# ESP32-S3 register map
Vendor: ESPRESSIF SYSTEMS (SHANGHAI) CO., LTD.; Series: ESP32 S-Series; File version: 22
CPU: Xtensa LX7 r0p0, little endian, no MPU, FPU, 0 interrupt priority bits
Address unit: 32 bits
Registers are 32-bit, read-write, reset 0x0 unless marked. A register's access mark holds for its fields unless they carry their own. Offsets are from the block's base; [hi:lo] are bit positions; {n}, {i} and the like mark numbered series.

## MCPWM0 — Motor Control Pulse-Width Modulation 0
Base 0x6001E000
Same registers: MCPWM1 0x6002C000
0x00 CLK_CFG — PWM clock prescaler register.
  [7:0] CLK_PRESCALE — Period of PWM_clk = 6.25ns * (PWM_CLK_PRESCALE + 1)
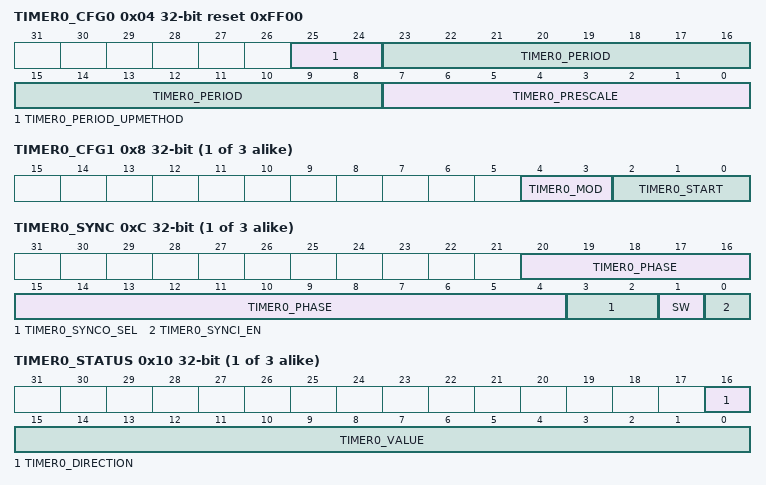
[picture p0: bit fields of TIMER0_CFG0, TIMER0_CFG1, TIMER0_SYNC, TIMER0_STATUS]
0x04 TIMER0_CFG0 reset 0xFF00 — PWM timer0 period and update method configuration register.
  [25:24] TIMER0_PERIOD_UPMETHOD — Update method for active register of PWM timer0 period, 0: immediate, 1: TEZ, 2: sync, 3: TEZ | sync. TEZ here and below means timer equal zero event
  [23:8] TIMER0_PERIOD — period shadow register of PWM timer0
  [7:0] TIMER0_PRESCALE — period of PT0_clk = Period of PWM_clk * (PWM_TIMER0_PRESCALE + 1)
{0x8+0x10*i} TIMER{i}_CFG1 (i=0..2) — PWM timer{i} working mode and start/stop control configuration register.
  [4:3] TIMER{i}_MOD — PWM timer{i} working mode, 0: freeze, 1: increase mode, 2: decrease mode, 3: up-down mode
  [2:0] TIMER{i}_START — PWM timer{i} start and stop control. 0: if PWM timer{i} starts, then stops at TEZ, 1: if timer{i} starts, then stops at TEP, 2: PWM timer{i} starts and runs on, 3: timer{i} starts and stops at the next TEZ, 4: timer{i} starts and stops at the next TEP. TEP here and below means the event that happens when the timer equals to period
{0xC+0x10*i} TIMER{i}_SYNC (i=0..2) — PWM timer{i} sync function configuration register.
  [20:4] TIMER{i}_PHASE — phase for timer reload on sync event
  [3:2] TIMER{i}_SYNCO_SEL — PWM timer{i} sync_out selection, 0: synci, 1: TEZ, 2: TEP, otherwise:sync out is software sync
  [1] SW — Toggling this bit will trigger a software sync.
  [0] TIMER{i}_SYNCI_EN — When set, timer reloading with phase on sync input event is enabled.
{0x10+0x10*i} TIMER{i}_STATUS ro (i=0..2) — PWM timer{i} status register.
  [16] TIMER{i}_DIRECTION — current PWM timer{i} counter direction, 0: increment 1: decrement
  [15:0] TIMER{i}_VALUE — current PWM timer{i} counter value
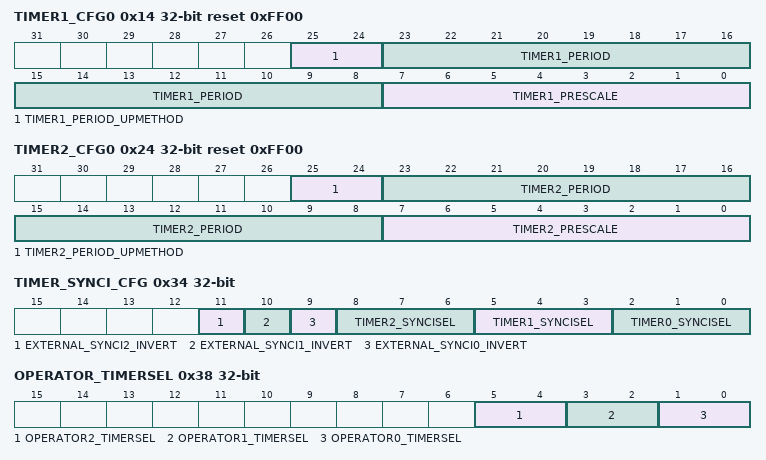
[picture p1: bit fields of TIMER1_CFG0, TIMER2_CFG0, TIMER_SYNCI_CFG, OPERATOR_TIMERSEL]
0x14 TIMER1_CFG0 reset 0xFF00 — PWM timer1 period and update method configuration register.
  [25:24] TIMER1_PERIOD_UPMETHOD — Update method for active register of PWM timer1 period, 0: immediate, 1: TEZ, 2: sync, 3: TEZ | sync. TEZ here and below means timer equal zero event
  [23:8] TIMER1_PERIOD — period shadow register of PWM timer1
  [7:0] TIMER1_PRESCALE — period of PT0_clk = Period of PWM_clk * (PWM_timer1_PRESCALE + 1)
0x24 TIMER2_CFG0 reset 0xFF00 — PWM timer2 period and update method configuration register.
  [25:24] TIMER2_PERIOD_UPMETHOD — Update method for active register of PWM timer2 period, 0: immediate, 1: TEZ, 2: sync, 3: TEZ | sync. TEZ here and below means timer equal zero event
  [23:8] TIMER2_PERIOD — period shadow register of PWM timer2
  [7:0] TIMER2_PRESCALE — period of PT0_clk = Period of PWM_clk * (PWM_timer2_PRESCALE + 1)
0x34 TIMER_SYNCI_CFG — Synchronization input selection for three PWM timers.
  [11] EXTERNAL_SYNCI2_INVERT — invert SYNC2 from GPIO matrix
  [10] EXTERNAL_SYNCI1_INVERT — invert SYNC1 from GPIO matrix
  [9] EXTERNAL_SYNCI0_INVERT — invert SYNC0 from GPIO matrix
  [8:6] TIMER2_SYNCISEL — select sync input for PWM timer2, 1: PWM timer0 sync_out, 2: PWM timer1 sync_out, 3: PWM timer2 sync_out, 4: SYNC0 from GPIO matrix, 5: SYNC1 from GPIO matrix, 6: SYNC2 from GPIO matrix, other values: no sync input selected
  [5:3] TIMER1_SYNCISEL — select sync input for PWM timer1, 1: PWM timer0 sync_out, 2: PWM timer1 sync_out, 3: PWM timer2 sync_out, 4: SYNC0 from GPIO matrix, 5: SYNC1 from GPIO matrix, 6: SYNC2 from GPIO matrix, other values: no sync input selected
  [2:0] TIMER0_SYNCISEL — select sync input for PWM timer0, 1: PWM timer0 sync_out, 2: PWM timer1 sync_out, 3: PWM timer2 sync_out, 4: SYNC0 from GPIO matrix, 5: SYNC1 from GPIO matrix, 6: SYNC2 from GPIO matrix, other values: no sync input selected
0x38 OPERATOR_TIMERSEL — Select specific timer for PWM operators.
  [5:4] OPERATOR2_TIMERSEL — Select which PWM timer's is the timing reference for PWM operator2, 0: timer0, 1: timer1, 2: timer2
  [3:2] OPERATOR1_TIMERSEL — Select which PWM timer's is the timing reference for PWM operator1, 0: timer0, 1: timer1, 2: timer2
  [1:0] OPERATOR0_TIMERSEL — Select which PWM timer's is the timing reference for PWM operator0, 0: timer0, 1: timer1, 2: timer2
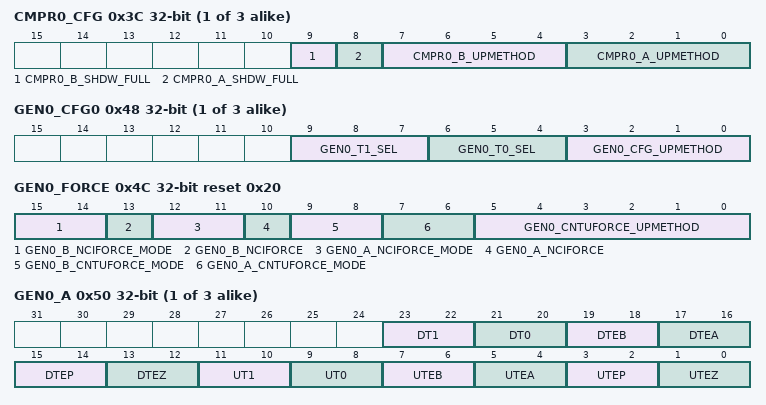
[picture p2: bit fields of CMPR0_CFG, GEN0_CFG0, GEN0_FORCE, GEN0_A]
{0x3C+0x38*i} CMPR{i}_CFG (i=0..2) — Transfer status and update method for time stamp registers A and B
  [9] CMPR{i}_B_SHDW_FULL — Set and reset by hardware. If set, PWM generator {i} time stamp B's shadow reg is filled and waiting to be transferred to B's active reg. If cleared, B's active reg has been updated with shadow register latest value
  [8] CMPR{i}_A_SHDW_FULL — Set and reset by hardware. If set, PWM generator {i} time stamp A's shadow reg is filled and waiting to be transferred to A's active reg. If cleared, A's active reg has been updated with shadow register latest value
  [7:4] CMPR{i}_B_UPMETHOD — Update method for PWM generator {i} time stamp B's active register. When all bits are set to 0: immediately, when bit0 is set to 1: TEZ, when bit1 is set to 1: TEP,when bit2 is set to 1: sync, when bit3 is set to 1: disable the update.
  [3:0] CMPR{i}_A_UPMETHOD — Update method for PWM generator {i} time stamp A's active register. When all bits are set to 0: immediately, when bit0 is set to 1: TEZ, when bit1 is set to 1: TEP,when bit2 is set to 1: sync, when bit3 is set to 1: disable the update.
{0x40+0x38*i} CMPR{i}_VALUE0 (i=0..2) — Shadow register for register A.
  [15:0] CMPR{i}_A — PWM generator {i} time stamp A's shadow register
{0x44+0x38*i} CMPR{i}_VALUE1 (i=0..2) — Shadow register for register B.
  [15:0] CMPR{i}_B — PWM generator {i} time stamp B's shadow register
{0x48+0x38*i} GEN{i}_CFG0 (i=0..2) — Fault event T0 and T1 handling
  [9:7] GEN{i}_T1_SEL — Source selection for PWM generator {i} event_t1, take effect immediately, 0: fault_event0, 1: fault_event1, 2: fault_event2, 3: sync_taken, 4: none
  [6:4] GEN{i}_T0_SEL — Source selection for PWM generator {i} event_t0, take effect immediately, 0: fault_event0, 1: fault_event1, 2: fault_event2, 3: sync_taken, 4: none
  [3:0] GEN{i}_CFG_UPMETHOD — Update method for PWM generator {i}'s active register of configuration. When all bits are set to 0: immediately, when bit0 is set to 1: TEZ, when bit1 is set to 1:
0x4C GEN0_FORCE reset 0x20 — Permissives to force PWM0A and PWM0B outputs by software
  [15:14] GEN0_B_NCIFORCE_MODE — non-continuous immediate software force mode for PWM0B, 0: disabled, 1: low, 2: high, 3: disabled
  [13] GEN0_B_NCIFORCE — Trigger of non-continuous immediate software-force event for PWM0B, a toggle will trigger a force event.
  [12:11] GEN0_A_NCIFORCE_MODE — non-continuous immediate software force mode for PWM0A, 0: disabled, 1: low, 2: high, 3: disabled
  [10] GEN0_A_NCIFORCE — Trigger of non-continuous immediate software-force event for PWM0A, a toggle will trigger a force event.
  [9:8] GEN0_B_CNTUFORCE_MODE — Continuous software force mode for PWM0B. 0: disabled, 1: low, 2: high, 3: disabled
  [7:6] GEN0_A_CNTUFORCE_MODE — Continuous software force mode for PWM0A. 0: disabled, 1: low, 2: high, 3: disabled
  [5:0] GEN0_CNTUFORCE_UPMETHOD — Updating method for continuous software force of PWM generator0. When all bits are set to 0: immediately, when bit0 is set to 1: TEZ,,when bit1 is set to 1: TEP, when bit2 is set to 1: TEA, when bit3 is set to 1: TEB, when bit4 is set to 1: sync, when bit5 is set to 1: disable update. (TEA/B here and below means an event generated when the timer's value equals to that of register A/B.)
{0x50+0x38*i} GEN{i}_A (i=0..2) — Actions triggered by events on PWM{i}A
  [23:22] DT1 — Action on PWM{i}A triggered by event_t1 when timer decreasing. 0: no change, 1: low, 2: high, 3: toggle
  [21:20] DT0 — Action on PWM{i}A triggered by event_t0 when timer decreasing
  [19:18] DTEB — Action on PWM{i}A triggered by event TEB when timer decreasing
  [17:16] DTEA — Action on PWM{i}A triggered by event TEA when timer decreasing
  [15:14] DTEP — Action on PWM{i}A triggered by event TEP when timer decreasing
  [13:12] DTEZ — Action on PWM{i}A triggered by event TEZ when timer decreasing
  [11:10] UT1 — Action on PWM{i}A triggered by event_t1 when timer increasing
  [9:8] UT0 — Action on PWM{i}A triggered by event_t0 when timer increasing
  [7:6] UTEB — Action on PWM{i}A triggered by event TEB when timer increasing
  [5:4] UTEA — Action on PWM{i}A triggered by event TEA when timer increasing
  [3:2] UTEP — Action on PWM{i}A triggered by event TEP when timer increasing
  [1:0] UTEZ — Action on PWM{i}A triggered by event TEZ when timer increasing
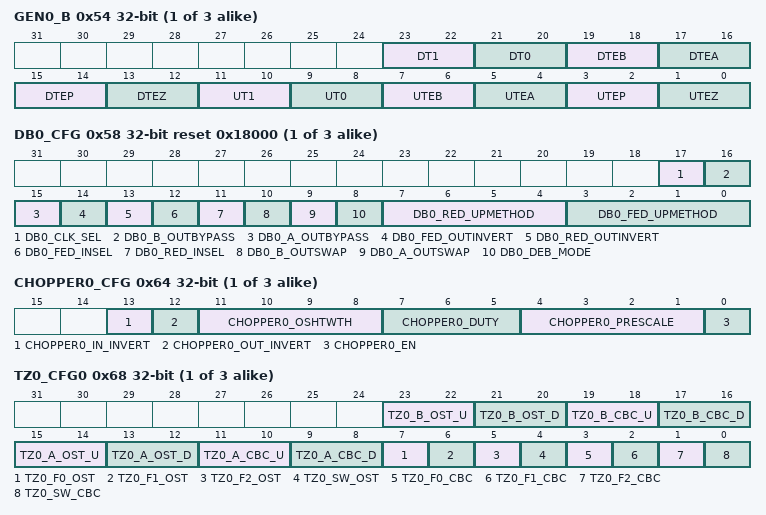
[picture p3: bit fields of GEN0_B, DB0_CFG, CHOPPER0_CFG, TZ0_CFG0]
{0x54+0x38*i} GEN{i}_B (i=0..2) — Actions triggered by events on PWM{i}B
  [23:22] DT1 — Action on PWM{i}B triggered by event_t1 when timer decreasing. 0: no change, 1: low, 2: high, 3: toggle
  [21:20] DT0 — Action on PWM{i}B triggered by event_t0 when timer decreasing
  [19:18] DTEB — Action on PWM{i}B triggered by event TEB when timer decreasing
  [17:16] DTEA — Action on PWM{i}B triggered by event TEA when timer decreasing
  [15:14] DTEP — Action on PWM{i}B triggered by event TEP when timer decreasing
  [13:12] DTEZ — Action on PWM{i}B triggered by event TEZ when timer decreasing
  [11:10] UT1 — Action on PWM{i}B triggered by event_t1 when timer increasing
  [9:8] UT0 — Action on PWM{i}B triggered by event_t0 when timer increasing
  [7:6] UTEB — Action on PWM{i}B triggered by event TEB when timer increasing
  [5:4] UTEA — Action on PWM{i}B triggered by event TEA when timer increasing
  [3:2] UTEP — Action on PWM{i}B triggered by event TEP when timer increasing
  [1:0] UTEZ — Action on PWM{i}B triggered by event TEZ when timer increasing
{0x58+0x38*i} DB{i}_CFG reset 0x18000 (i=0..2) — dead time type selection and configuration
  [17] DB{i}_CLK_SEL — Dead time generator {i} clock selection. 0: PWM_clk, 1: PT_clk
  [16] DB{i}_B_OUTBYPASS — S0 in documentation
  [15] DB{i}_A_OUTBYPASS — S1 in documentation
  [14] DB{i}_FED_OUTINVERT — S3 in documentation
  [13] DB{i}_RED_OUTINVERT — S2 in documentation
  [12] DB{i}_FED_INSEL — S5 in documentation
  [11] DB{i}_RED_INSEL — S4 in documentation
  [10] DB{i}_B_OUTSWAP — S7 in documentation
  [9] DB{i}_A_OUTSWAP — S6 in documentation
  [8] DB{i}_DEB_MODE — S8 in documentation, dual-edge B mode, 0: fed/red take effect on different path separately, 1: fed/red take effect on B path, A out is in bypass or dulpB mode
  [7:4] DB{i}_RED_UPMETHOD — Update method for RED (rising edge delay) active register. 0: immediate, bit0: tez, bit1: tep, bit2: sync, bit3: freeze
  [3:0] DB{i}_FED_UPMETHOD — Update method for FED (falling edge delay) active register. 0: immediate, bit0: tez, bit1: tep, bit2: sync, bit3: freeze
{0x5C+0x38*i} DB{i}_FED_CFG (i=0..2) — Shadow register for falling edge delay (FED).
  [15:0] DB{i}_FED — Shadow register for FED
{0x60+0x38*i} DB{i}_RED_CFG (i=0..2) — Shadow register for rising edge delay (RED).
  [15:0] DB{i}_RED — Shadow register for RED
{0x64+0x38*i} CHOPPER{i}_CFG (i=0..2) — Carrier enable and configuratoin
  [13] CHOPPER{i}_IN_INVERT — when set, invert the input of PWM{i}A and PWM{i}B for this submodule
  [12] CHOPPER{i}_OUT_INVERT — when set, invert the output of PWM{i}A and PWM{i}B for this submodule
  [11:8] CHOPPER{i}_OSHTWTH — width of the fist pulse in number of periods of the carrier
  [7:5] CHOPPER{i}_DUTY — carrier duty selection. Duty = PWM_CARRIER0_DUTY / 8
  [4:1] CHOPPER{i}_PRESCALE — PWM carrier0 clock (PC_clk) prescale value. Period of PC_clk = period of PWM_clk * (PWM_CARRIER0_PRESCALE + 1)
  [0] CHOPPER{i}_EN — When set, carrier0 function is enabled. When cleared, carrier0 is bypassed
{0x68+0x38*i} TZ{i}_CFG0 (i=0..2) — Actions on PWM{i}A and PWM{i}B trip events
  [23:22] TZ{i}_B_OST_U — One-shot mode action on PWM{i}B when fault event occurs and timer is increasing. 0: do nothing, 1: force lo, 2: force hi, 3: toggle
  [21:20] TZ{i}_B_OST_D — One-shot mode action on PWM{i}B when fault event occurs and timer is decreasing. 0: do nothing, 1: force lo, 2: force hi, 3: toggle
  [19:18] TZ{i}_B_CBC_U — Cycle-by-cycle mode action on PWM{i}B when fault event occurs and timer is increasing. 0: do nothing, 1: force lo, 2: force hi, 3: toggle
  [17:16] TZ{i}_B_CBC_D — Cycle-by-cycle mode action on PWM{i}B when fault event occurs and timer is decreasing. 0: do nothing, 1: force lo, 2: force hi, 3: toggle
  [15:14] TZ{i}_A_OST_U — One-shot mode action on PWM{i}A when fault event occurs and timer is increasing. 0: do nothing, 1: force lo, 2: force hi, 3: toggle
  [13:12] TZ{i}_A_OST_D — One-shot mode action on PWM{i}A when fault event occurs and timer is decreasing. 0: do nothing, 1: force lo, 2: force hi, 3: toggle
  [11:10] TZ{i}_A_CBC_U — Cycle-by-cycle mode action on PWM{i}A when fault event occurs and timer is increasing. 0: do nothing, 1: force lo, 2: force hi, 3: toggle
  [9:8] TZ{i}_A_CBC_D — Cycle-by-cycle mode action on PWM{i}A when fault event occurs and timer is decreasing. 0: do nothing, 1: force lo, 2: force hi, 3: toggle
  [7] TZ{i}_F0_OST — event_f0 will trigger one-shot mode action. 0: disable, 1: enable
  [6] TZ{i}_F1_OST — event_f1 will trigger one-shot mode action. 0: disable, 1: enable
  [5] TZ{i}_F2_OST — event_f2 will trigger one-shot mode action. 0: disable, 1: enable
  [4] TZ{i}_SW_OST — Enable register for software force one-shot mode action. 0: disable, 1: enable
  [3] TZ{i}_F0_CBC — event_f0 will trigger cycle-by-cycle mode action. 0: disable, 1: enable
  [2] TZ{i}_F1_CBC — event_f1 will trigger cycle-by-cycle mode action. 0: disable, 1: enable
  [1] TZ{i}_F2_CBC — event_f2 will trigger cycle-by-cycle mode action. 0: disable, 1: enable
  [0] TZ{i}_SW_CBC — Enable register for software force cycle-by-cycle mode action. 0: disable, 1: enable
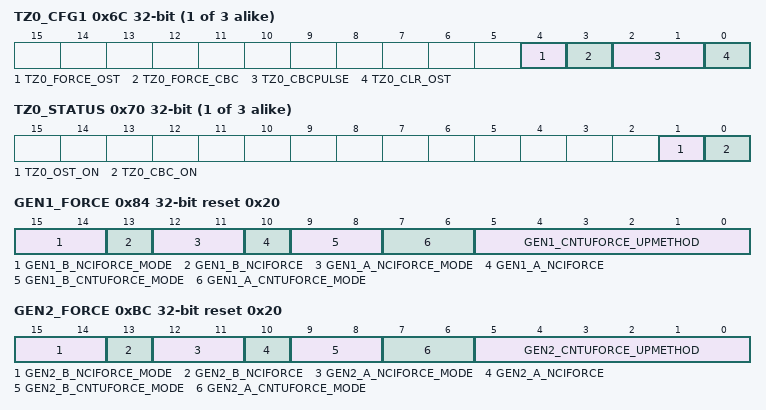
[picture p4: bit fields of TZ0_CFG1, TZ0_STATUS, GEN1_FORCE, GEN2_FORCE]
{0x6C+0x38*i} TZ{i}_CFG1 (i=0..2) — Software triggers for fault handler actions
  [4] TZ{i}_FORCE_OST — a toggle (software negate its value) triggers a one-shot mode action
  [3] TZ{i}_FORCE_CBC — a toggle trigger a cycle-by-cycle mode action
  [2:1] TZ{i}_CBCPULSE — cycle-by-cycle mode action refresh moment selection. Bit0: TEZ, bit1:TEP
  [0] TZ{i}_CLR_OST — a rising edge will clear on going one-shot mode action
{0x70+0x38*i} TZ{i}_STATUS ro (i=0..2) — Status of fault events.
  [1] TZ{i}_OST_ON — Set and reset by hardware. If set, an one-shot mode action is on going
  [0] TZ{i}_CBC_ON — Set and reset by hardware. If set, a cycle-by-cycle mode action is on going
0x84 GEN1_FORCE reset 0x20 — Permissives to force PWM1A and PWM1B outputs by software
  [15:14] GEN1_B_NCIFORCE_MODE — non-continuous immediate software force mode for PWM1B, 0: disabled, 1: low, 2: high, 3: disabled
  [13] GEN1_B_NCIFORCE — Trigger of non-continuous immediate software-force event for PWM1B, a toggle will trigger a force event.
  [12:11] GEN1_A_NCIFORCE_MODE — non-continuous immediate software force mode for PWM1A, 0: disabled, 1: low, 2: high, 3: disabled
  [10] GEN1_A_NCIFORCE — Trigger of non-continuous immediate software-force event for PWM1A, a toggle will trigger a force event.
  [9:8] GEN1_B_CNTUFORCE_MODE — Continuous software force mode for PWM1B. 0: disabled, 1: low, 2: high, 3: disabled
  [7:6] GEN1_A_CNTUFORCE_MODE — Continuous software force mode for PWM1A. 0: disabled, 1: low, 2: high, 3: disabled
  [5:0] GEN1_CNTUFORCE_UPMETHOD — Updating method for continuous software force of PWM generator 1. When all bits are set to 0: immediately, when bit0 is set to 1: TEZ,,when bit1 is set to 1: TEP, when bit2 is set to 1: TEA, when bit3 is set to 1: TEB, when bit4 is set to 1: sync, when bit5 is set to 1: disable update. (TEA/B here and below means an event generated when the timer's value equals to that of register A/B.)
0xBC GEN2_FORCE reset 0x20 — Permissives to force PWM2A and PWM2B outputs by software
  [15:14] GEN2_B_NCIFORCE_MODE — non-continuous immediate software force mode for PWM2B, 0: disabled, 1: low, 2: high, 3: disabled
  [13] GEN2_B_NCIFORCE — Trigger of non-continuous immediate software-force event for PWM2B, a toggle will trigger a force event.
  [12:11] GEN2_A_NCIFORCE_MODE — non-continuous immediate software force mode for PWM2A, 0: disabled, 1: low, 2: high, 3: disabled
  [10] GEN2_A_NCIFORCE — Trigger of non-continuous immediate software-force event for PWM2A, a toggle will trigger a force event.
  [9:8] GEN2_B_CNTUFORCE_MODE — Continuous software force mode for PWM2B. 0: disabled, 1: low, 2: high, 3: disabled
  [7:6] GEN2_A_CNTUFORCE_MODE — Continuous software force mode for PWM2A. 0: disabled, 1: low, 2: high, 3: disabled
  [5:0] GEN2_CNTUFORCE_UPMETHOD — Updating method for continuous software force of PWM generator 2. When all bits are set to 0: immediately, when bit0 is set to 1: TEZ,,when bit1 is set to 1: TEP, when bit2 is set to 1: TEA, when bit3 is set to 1: TEB, when bit4 is set to 1: sync, when bit5 is set to 1: disable update. (TEA/B here and below means an event generated when the timer's value equals to that of register A/B.)
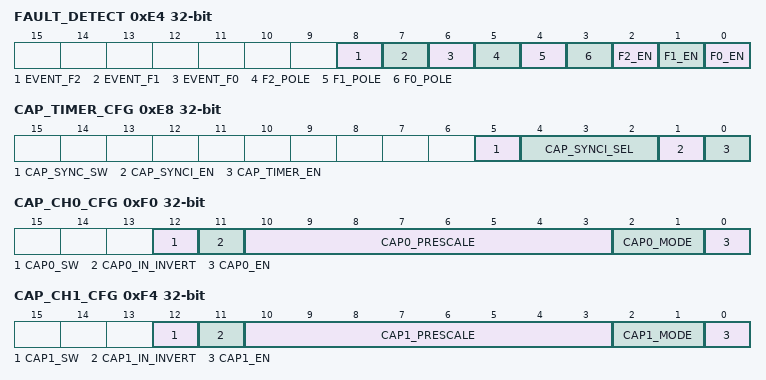
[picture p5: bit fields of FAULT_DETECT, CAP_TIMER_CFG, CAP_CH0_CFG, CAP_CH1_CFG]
0xE4 FAULT_DETECT access per field — Fault detection configuration and status
  [8] EVENT_F2 ro — Set and reset by hardware. If set, event_f2 is on going
  [7] EVENT_F1 ro — Set and reset by hardware. If set, event_f1 is on going
  [6] EVENT_F0 ro — Set and reset by hardware. If set, event_f0 is on going
  [5] F2_POLE rw — Set event_f2 trigger polarity on FAULT2 source from GPIO matrix. 0: level low, 1: level high
  [4] F1_POLE rw — Set event_f1 trigger polarity on FAULT2 source from GPIO matrix. 0: level low, 1: level high
  [3] F0_POLE rw — Set event_f0 trigger polarity on FAULT2 source from GPIO matrix. 0: level low, 1: level high
  [2] F2_EN rw — When set, event_f2 generation is enabled
  [1] F1_EN rw — When set, event_f1 generation is enabled
  [0] F0_EN rw — When set, event_f0 generation is enabled
0xE8 CAP_TIMER_CFG access per field — Configure capture timer
  [5] CAP_SYNC_SW wo — Write 1 will force a capture timer sync, capture timer is loaded with value in phase register.
  [4:2] CAP_SYNCI_SEL rw — capture module sync input selection. 0: none, 1: timer0 sync_out, 2: timer1 sync_out, 3: timer2 sync_out, 4: SYNC0 from GPIO matrix, 5: SYNC1 from GPIO matrix, 6: SYNC2 from GPIO matrix
  [1] CAP_SYNCI_EN rw — When set, capture timer sync is enabled.
  [0] CAP_TIMER_EN rw — When set, capture timer incrementing under APB_clk is enabled.
0xEC CAP_TIMER_PHASE — Phase for capture timer sync
  [31:0] CAP_PHASE — Phase value for capture timer sync operation.
0xF0 CAP_CH0_CFG access per field — Capture channel 0 configuration and enable
  [12] CAP0_SW wo — Write 1 will trigger a software forced capture on channel 0
  [11] CAP0_IN_INVERT rw — when set, CAP0 form GPIO matrix is inverted before prescale
  [10:3] CAP0_PRESCALE rw — Value of prescaling on possitive edge of CAP0. Prescale value = PWM_CAP0_PRESCALE + 1
  [2:1] CAP0_MODE rw — Edge of capture on channel 0 after prescaling. When bit0 is set to 1: enable capture on the negative edge, When bit1 is set to 1: enable capture on the positive edge.
  [0] CAP0_EN rw — When set, capture on channel 0 is enabled
0xF4 CAP_CH1_CFG access per field — Capture channel 1 configuration and enable
  [12] CAP1_SW wo — Write 1 will trigger a software forced capture on channel 1
  [11] CAP1_IN_INVERT rw — when set, CAP1 form GPIO matrix is inverted before prescale
  [10:3] CAP1_PRESCALE rw — Value of prescaling on possitive edge of CAP1. Prescale value = PWM_CAP1_PRESCALE + 1
  [2:1] CAP1_MODE rw — Edge of capture on channel 1 after prescaling. When bit0 is set to 1: enable capture on the negative edge, When bit1 is set to 1: enable capture on the positive edge.
  [0] CAP1_EN rw — When set, capture on channel 2 is enabled
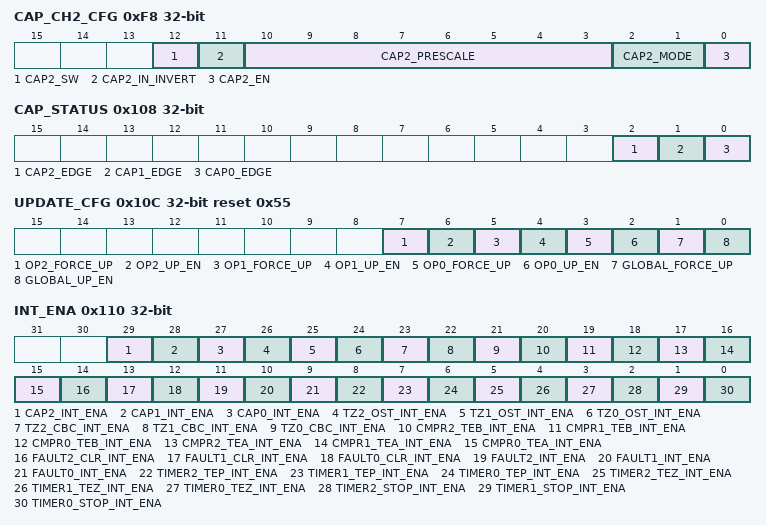
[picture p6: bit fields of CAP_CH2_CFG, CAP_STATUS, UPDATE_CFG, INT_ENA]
0xF8 CAP_CH2_CFG access per field — Capture channel 2 configuration and enable
  [12] CAP2_SW wo — Write 1 will trigger a software forced capture on channel 2
  [11] CAP2_IN_INVERT rw — when set, CAP2 form GPIO matrix is inverted before prescale
  [10:3] CAP2_PRESCALE rw — Value of prescaling on possitive edge of CAP2. Prescale value = PWM_CAP2_PRESCALE + 1
  [2:1] CAP2_MODE rw — Edge of capture on channel 2 after prescaling. When bit0 is set to 1: enable capture on the negative edge, When bit1 is set to 1: enable capture on the positive edge.
  [0] CAP2_EN rw — When set, capture on channel 2 is enabled
{0xFC+4i} CAP_CH{i} ro (i=0..2) — Value of last capture on channel {i}
  [31:0] CAP{i}_VALUE
0x108 CAP_STATUS ro — Edge of last capture trigger
  [2] CAP2_EDGE — Edge of last capture trigger on channel 2, 0: posedge, 1: negedge
  [1] CAP1_EDGE — Edge of last capture trigger on channel 1, 0: posedge, 1: negedge
  [0] CAP0_EDGE — Edge of last capture trigger on channel 0, 0: posedge, 1: negedge
0x10C UPDATE_CFG reset 0x55 — Enable update.
  [7] OP2_FORCE_UP — a toggle (software invert its value) will trigger a forced update of active registers in PWM operator 2
  [6] OP2_UP_EN — When set and PWM_GLOBAL_UP_EN is set, update of active registers in PWM operator 2 are enabled
  [5] OP1_FORCE_UP — a toggle (software invert its value) will trigger a forced update of active registers in PWM operator 1
  [4] OP1_UP_EN — When set and PWM_GLOBAL_UP_EN is set, update of active registers in PWM operator 1 are enabled
  [3] OP0_FORCE_UP — a toggle (software invert its value) will trigger a forced update of active registers in PWM operator 0
  [2] OP0_UP_EN — When set and PWM_GLOBAL_UP_EN is set, update of active registers in PWM operator 0 are enabled
  [1] GLOBAL_FORCE_UP — a toggle (software invert its value) will trigger a forced update of all active registers in MCPWM module
  [0] GLOBAL_UP_EN — The global enable of update of all active registers in MCPWM module
0x110 INT_ENA — Interrupt enable bits
  [29] CAP2_INT_ENA — The enable bit for the interrupt triggered by capture on channel 2.
  [28] CAP1_INT_ENA — The enable bit for the interrupt triggered by capture on channel 1.
  [27] CAP0_INT_ENA — The enable bit for the interrupt triggered by capture on channel 0.
  [26] TZ2_OST_INT_ENA — The enable bit for the interrupt triggered by a one-shot mode action on PWM2.
  [25] TZ1_OST_INT_ENA — The enable bit for the interrupt triggered by a one-shot mode action on PWM1.
  [24] TZ0_OST_INT_ENA — The enable bit for the interrupt triggered by a one-shot mode action on PWM0.
  [23] TZ2_CBC_INT_ENA — The enable bit for the interrupt triggered by a cycle-by-cycle mode action on PWM2.
  [22] TZ1_CBC_INT_ENA — The enable bit for the interrupt triggered by a cycle-by-cycle mode action on PWM1.
  [21] TZ0_CBC_INT_ENA — The enable bit for the interrupt triggered by a cycle-by-cycle mode action on PWM0.
  [20] CMPR2_TEB_INT_ENA — The enable bit for the interrupt triggered by a PWM operator 2 TEB event
  [19] CMPR1_TEB_INT_ENA — The enable bit for the interrupt triggered by a PWM operator 1 TEB event
  [18] CMPR0_TEB_INT_ENA — The enable bit for the interrupt triggered by a PWM operator 0 TEB event
  [17] CMPR2_TEA_INT_ENA — The enable bit for the interrupt triggered by a PWM operator 2 TEA event
  [16] CMPR1_TEA_INT_ENA — The enable bit for the interrupt triggered by a PWM operator 1 TEA event
  [15] CMPR0_TEA_INT_ENA — The enable bit for the interrupt triggered by a PWM operator 0 TEA event
  [14] FAULT2_CLR_INT_ENA — The enable bit for the interrupt triggered when event_f2 ends.
  [13] FAULT1_CLR_INT_ENA — The enable bit for the interrupt triggered when event_f1 ends.
  [12] FAULT0_CLR_INT_ENA — The enable bit for the interrupt triggered when event_f0 ends.
  [11] FAULT2_INT_ENA — The enable bit for the interrupt triggered when event_f2 starts.
  [10] FAULT1_INT_ENA — The enable bit for the interrupt triggered when event_f1 starts.
  [9] FAULT0_INT_ENA — The enable bit for the interrupt triggered when event_f0 starts.
  [8] TIMER2_TEP_INT_ENA — The enable bit for the interrupt triggered by a PWM timer 2 TEP event.
  [7] TIMER1_TEP_INT_ENA — The enable bit for the interrupt triggered by a PWM timer 1 TEP event.
  [6] TIMER0_TEP_INT_ENA — The enable bit for the interrupt triggered by a PWM timer 0 TEP event.
  [5] TIMER2_TEZ_INT_ENA — The enable bit for the interrupt triggered by a PWM timer 2 TEZ event.
  [4] TIMER1_TEZ_INT_ENA — The enable bit for the interrupt triggered by a PWM timer 1 TEZ event.
  [3] TIMER0_TEZ_INT_ENA — The enable bit for the interrupt triggered by a PWM timer 0 TEZ event.
  [2] TIMER2_STOP_INT_ENA — The enable bit for the interrupt triggered when the timer 2 stops.
  [1] TIMER1_STOP_INT_ENA — The enable bit for the interrupt triggered when the timer 1 stops.
  [0] TIMER0_STOP_INT_ENA — The enable bit for the interrupt triggered when the timer 0 stops.
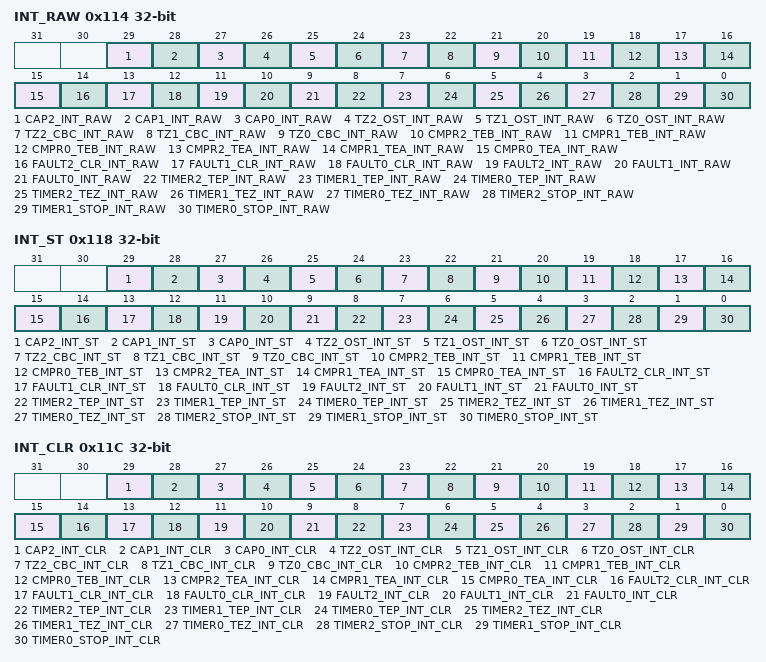
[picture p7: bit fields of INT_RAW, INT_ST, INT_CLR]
0x114 INT_RAW — Raw interrupt status
  [29] CAP2_INT_RAW — The raw status bit for the interrupt triggered by capture on channel 2.
  [28] CAP1_INT_RAW — The raw status bit for the interrupt triggered by capture on channel 1.
  [27] CAP0_INT_RAW — The raw status bit for the interrupt triggered by capture on channel 0.
  [26] TZ2_OST_INT_RAW — The raw status bit for the interrupt triggered by a one-shot mode action on PWM2.
  [25] TZ1_OST_INT_RAW — The raw status bit for the interrupt triggered by a one-shot mode action on PWM1.
  [24] TZ0_OST_INT_RAW — The raw status bit for the interrupt triggered by a one-shot mode action on PWM0.
  [23] TZ2_CBC_INT_RAW — The raw status bit for the interrupt triggered by a cycle-by-cycle mode action on PWM2.
  [22] TZ1_CBC_INT_RAW — The raw status bit for the interrupt triggered by a cycle-by-cycle mode action on PWM1.
  [21] TZ0_CBC_INT_RAW — The raw status bit for the interrupt triggered by a cycle-by-cycle mode action on PWM0.
  [20] CMPR2_TEB_INT_RAW — The raw status bit for the interrupt triggered by a PWM operator 2 TEB event
  [19] CMPR1_TEB_INT_RAW — The raw status bit for the interrupt triggered by a PWM operator 1 TEB event
  [18] CMPR0_TEB_INT_RAW — The raw status bit for the interrupt triggered by a PWM operator 0 TEB event
  [17] CMPR2_TEA_INT_RAW — The raw status bit for the interrupt triggered by a PWM operator 2 TEA event
  [16] CMPR1_TEA_INT_RAW — The raw status bit for the interrupt triggered by a PWM operator 1 TEA event
  [15] CMPR0_TEA_INT_RAW — The raw status bit for the interrupt triggered by a PWM operator 0 TEA event
  [14] FAULT2_CLR_INT_RAW — The raw status bit for the interrupt triggered when event_f2 ends.
  [13] FAULT1_CLR_INT_RAW — The raw status bit for the interrupt triggered when event_f1 ends.
  [12] FAULT0_CLR_INT_RAW — The raw status bit for the interrupt triggered when event_f0 ends.
  [11] FAULT2_INT_RAW — The raw status bit for the interrupt triggered when event_f2 starts.
  [10] FAULT1_INT_RAW — The raw status bit for the interrupt triggered when event_f1 starts.
  [9] FAULT0_INT_RAW — The raw status bit for the interrupt triggered when event_f0 starts.
  [8] TIMER2_TEP_INT_RAW — The raw status bit for the interrupt triggered by a PWM timer 2 TEP event.
  [7] TIMER1_TEP_INT_RAW — The raw status bit for the interrupt triggered by a PWM timer 1 TEP event.
  [6] TIMER0_TEP_INT_RAW — The raw status bit for the interrupt triggered by a PWM timer 0 TEP event.
  [5] TIMER2_TEZ_INT_RAW — The raw status bit for the interrupt triggered by a PWM timer 2 TEZ event.
  [4] TIMER1_TEZ_INT_RAW — The raw status bit for the interrupt triggered by a PWM timer 1 TEZ event.
  [3] TIMER0_TEZ_INT_RAW — The raw status bit for the interrupt triggered by a PWM timer 0 TEZ event.
  [2] TIMER2_STOP_INT_RAW — The raw status bit for the interrupt triggered when the timer 2 stops.
  [1] TIMER1_STOP_INT_RAW — The raw status bit for the interrupt triggered when the timer 1 stops.
  [0] TIMER0_STOP_INT_RAW — The raw status bit for the interrupt triggered when the timer 0 stops.
0x118 INT_ST ro — Masked interrupt status
  [29] CAP2_INT_ST — The masked status bit for the interrupt triggered by capture on channel 2.
  [28] CAP1_INT_ST — The masked status bit for the interrupt triggered by capture on channel 1.
  [27] CAP0_INT_ST — The masked status bit for the interrupt triggered by capture on channel 0.
  [26] TZ2_OST_INT_ST — The masked status bit for the interrupt triggered by a one-shot mode action on PWM2.
  [25] TZ1_OST_INT_ST — The masked status bit for the interrupt triggered by a one-shot mode action on PWM1.
  [24] TZ0_OST_INT_ST — The masked status bit for the interrupt triggered by a one-shot mode action on PWM0.
  [23] TZ2_CBC_INT_ST — The masked status bit for the interrupt triggered by a cycle-by-cycle mode action on PWM2.
  [22] TZ1_CBC_INT_ST — The masked status bit for the interrupt triggered by a cycle-by-cycle mode action on PWM1.
  [21] TZ0_CBC_INT_ST — The masked status bit for the interrupt triggered by a cycle-by-cycle mode action on PWM0.
  [20] CMPR2_TEB_INT_ST — The masked status bit for the interrupt triggered by a PWM operator 2 TEB event
  [19] CMPR1_TEB_INT_ST — The masked status bit for the interrupt triggered by a PWM operator 1 TEB event
  [18] CMPR0_TEB_INT_ST — The masked status bit for the interrupt triggered by a PWM operator 0 TEB event
  [17] CMPR2_TEA_INT_ST — The masked status bit for the interrupt triggered by a PWM operator 2 TEA event
  [16] CMPR1_TEA_INT_ST — The masked status bit for the interrupt triggered by a PWM operator 1 TEA event
  [15] CMPR0_TEA_INT_ST — The masked status bit for the interrupt triggered by a PWM operator 0 TEA event
  [14] FAULT2_CLR_INT_ST — The masked status bit for the interrupt triggered when event_f2 ends.
  [13] FAULT1_CLR_INT_ST — The masked status bit for the interrupt triggered when event_f1 ends.
  [12] FAULT0_CLR_INT_ST — The masked status bit for the interrupt triggered when event_f0 ends.
  [11] FAULT2_INT_ST — The masked status bit for the interrupt triggered when event_f2 starts.
  [10] FAULT1_INT_ST — The masked status bit for the interrupt triggered when event_f1 starts.
  [9] FAULT0_INT_ST — The masked status bit for the interrupt triggered when event_f0 starts.
  [8] TIMER2_TEP_INT_ST — The masked status bit for the interrupt triggered by a PWM timer 2 TEP event.
  [7] TIMER1_TEP_INT_ST — The masked status bit for the interrupt triggered by a PWM timer 1 TEP event.
  [6] TIMER0_TEP_INT_ST — The masked status bit for the interrupt triggered by a PWM timer 0 TEP event.
  [5] TIMER2_TEZ_INT_ST — The masked status bit for the interrupt triggered by a PWM timer 2 TEZ event.
  [4] TIMER1_TEZ_INT_ST — The masked status bit for the interrupt triggered by a PWM timer 1 TEZ event.
  [3] TIMER0_TEZ_INT_ST — The masked status bit for the interrupt triggered by a PWM timer 0 TEZ event.
  [2] TIMER2_STOP_INT_ST — The masked status bit for the interrupt triggered when the timer 2 stops.
  [1] TIMER1_STOP_INT_ST — The masked status bit for the interrupt triggered when the timer 1 stops.
  [0] TIMER0_STOP_INT_ST — The masked status bit for the interrupt triggered when the timer 0 stops.
0x11C INT_CLR wo — Interrupt clear bits
  [29] CAP2_INT_CLR — Set this bit to clear the interrupt triggered by capture on channel 2.
  [28] CAP1_INT_CLR — Set this bit to clear the interrupt triggered by capture on channel 1.
  [27] CAP0_INT_CLR — Set this bit to clear the interrupt triggered by capture on channel 0.
  [26] TZ2_OST_INT_CLR — Set this bit to clear the interrupt triggered by a one-shot mode action on PWM2.
  [25] TZ1_OST_INT_CLR — Set this bit to clear the interrupt triggered by a one-shot mode action on PWM1.
  [24] TZ0_OST_INT_CLR — Set this bit to clear the interrupt triggered by a one-shot mode action on PWM0.
  [23] TZ2_CBC_INT_CLR — Set this bit to clear the interrupt triggered by a cycle-by-cycle mode action on PWM2.
  [22] TZ1_CBC_INT_CLR — Set this bit to clear the interrupt triggered by a cycle-by-cycle mode action on PWM1.
  [21] TZ0_CBC_INT_CLR — Set this bit to clear the interrupt triggered by a cycle-by-cycle mode action on PWM0.
  [20] CMPR2_TEB_INT_CLR — Set this bit to clear the interrupt triggered by a PWM operator 2 TEB event
  [19] CMPR1_TEB_INT_CLR — Set this bit to clear the interrupt triggered by a PWM operator 1 TEB event
  [18] CMPR0_TEB_INT_CLR — Set this bit to clear the interrupt triggered by a PWM operator 0 TEB event
  [17] CMPR2_TEA_INT_CLR — Set this bit to clear the interrupt triggered by a PWM operator 2 TEA event
  [16] CMPR1_TEA_INT_CLR — Set this bit to clear the interrupt triggered by a PWM operator 1 TEA event
  [15] CMPR0_TEA_INT_CLR — Set this bit to clear the interrupt triggered by a PWM operator 0 TEA event
  [14] FAULT2_CLR_INT_CLR — Set this bit to clear the interrupt triggered when event_f2 ends.
  [13] FAULT1_CLR_INT_CLR — Set this bit to clear the interrupt triggered when event_f1 ends.
  [12] FAULT0_CLR_INT_CLR — Set this bit to clear the interrupt triggered when event_f0 ends.
  [11] FAULT2_INT_CLR — Set this bit to clear the interrupt triggered when event_f2 starts.
  [10] FAULT1_INT_CLR — Set this bit to clear the interrupt triggered when event_f1 starts.
  [9] FAULT0_INT_CLR — Set this bit to clear the interrupt triggered when event_f0 starts.
  [8] TIMER2_TEP_INT_CLR — Set this bit to clear the interrupt triggered by a PWM timer 2 TEP event.
  [7] TIMER1_TEP_INT_CLR — Set this bit to clear the interrupt triggered by a PWM timer 1 TEP event.
  [6] TIMER0_TEP_INT_CLR — Set this bit to clear the interrupt triggered by a PWM timer 0 TEP event.
  [5] TIMER2_TEZ_INT_CLR — Set this bit to clear the interrupt triggered by a PWM timer 2 TEZ event.
  [4] TIMER1_TEZ_INT_CLR — Set this bit to clear the interrupt triggered by a PWM timer 1 TEZ event.
  [3] TIMER0_TEZ_INT_CLR — Set this bit to clear the interrupt triggered by a PWM timer 0 TEZ event.
  [2] TIMER2_STOP_INT_CLR — Set this bit to clear the interrupt triggered when the timer 2 stops.
  [1] TIMER1_STOP_INT_CLR — Set this bit to clear the interrupt triggered when the timer 1 stops.
  [0] TIMER0_STOP_INT_CLR — Set this bit to clear the interrupt triggered when the timer 0 stops.
0x120 CLK — MCPWM APB configuration register
  [0] EN — Force clock on for this register file
0x124 VERSION reset 0x1509110
  [27:0] DATE — Version of this register file
